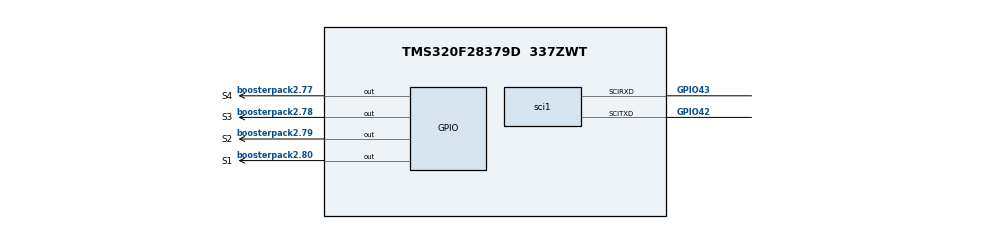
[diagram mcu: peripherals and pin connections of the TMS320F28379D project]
/**
 * These arguments were used when this file was generated. They will be automatically applied on subsequent loads
 * via the GUI or CLI. Run CLI with '--help' for additional information on how to override these arguments.
 * @cliArgs --board "/boards/LAUNCHXL_F28379D" --device "F2837xD" --part "F2837xD_337ZWT" --package "F2837xD_337ZWT" --context "CPU1" --product "C2000WARE@26.00.00.00"
 * @v2CliArgs --board "/boards/LAUNCHXL_F28379D" --device "TMS320F28379D" --package "337ZWT" --context "CPU1" --product "C2000WARE@26.00.00.00"
 * @versions {"tool":"1.27.0+4565"}
 */

/**
 * Import the modules used in this configuration.
 */
const cla              = scripting.addModule("/driverlib/cla.js", {}, false);
const cla1             = cla.addInstance();
const cputimer         = scripting.addModule("/driverlib/cputimer.js", {}, false);
const cputimer1        = cputimer.addInstance();
const gpio             = scripting.addModule("/driverlib/gpio.js", {}, false);
const gpio1            = gpio.addInstance();
const gpio2            = gpio.addInstance();
const gpio3            = gpio.addInstance();
const gpio4            = gpio.addInstance();
const inputxbar_input  = scripting.addModule("/driverlib/inputxbar_input.js", {}, false);
const inputxbar_input1 = inputxbar_input.addInstance();
const inputxbar_input2 = inputxbar_input.addInstance();
const inputxbar_input3 = inputxbar_input.addInstance();
const inputxbar_input4 = inputxbar_input.addInstance();
const memcfg           = scripting.addModule("/driverlib/memcfg.js");
const sci              = scripting.addModule("/driverlib/sci.js", {}, false);
const sci1             = sci.addInstance();

/**
 * Write custom configuration values to the imported modules.
 */
cla1.$name             = "myCLA0";
cla1.enable_CLA_TASK_2 = false;
cla1.enable_CLA_TASK_3 = false;
cla1.enable_CLA_TASK_4 = false;
cla1.enable_CLA_TASK_5 = false;
cla1.enable_CLA_TASK_6 = false;
cla1.enable_CLA_TASK_8 = false;
cla1.enable_CLA_TASK_7 = false;
cla1.cpuint_CLA_TASK_2 = false;
cla1.cpuint_CLA_TASK_3 = false;
cla1.cpuint_CLA_TASK_4 = false;
cla1.cpuint_CLA_TASK_5 = false;
cla1.cpuint_CLA_TASK_6 = false;
cla1.cpuint_CLA_TASK_7 = false;
cla1.cpuint_CLA_TASK_8 = false;

cputimer1.$name                    = "myCPUTIMER0";
cputimer1.timerPeriod              = 499;
cputimer1.enableInterrupt          = true;
cputimer1.startTimer               = true;
cputimer1.registerInterrupts       = true;
cputimer1.timerInt.enableInterrupt = true;

gpio1.$name                     = "S1";
gpio1.useInterrupt              = true;
gpio1.gpioPin.$assign           = "boosterpack2.80";
gpio1.xint.intType              = "GPIO_INT_TYPE_BOTH_EDGES";
gpio1.xint.enableInt            = true;
gpio1.xint.registerInterrupts   = true;
gpio1.xint.xInt.enableInterrupt = true;
scripting.suppress("Connected to hardware,@@@.+?@@@ is connected to EPWM4 BP on the LaunchPad F28379D\\. Consider selecting it in \'use hardware\' above\\. @@@.+?@@@", gpio1, "gpioPin");

gpio2.$name                     = "S2";
gpio2.useInterrupt              = true;
gpio2.gpioPin.$assign           = "boosterpack2.79";
gpio2.xint.intType              = "GPIO_INT_TYPE_BOTH_EDGES";
gpio2.xint.enableInt            = true;
gpio2.xint.registerInterrupts   = true;
gpio2.xint.xintNum              = "GPIO_INT_XINT2";
gpio2.xint.xInt.enableInterrupt = true;
scripting.suppress("Connected to hardware,@@@.+?@@@ is connected to EPWM4 BP on the LaunchPad F28379D\\. Consider selecting it in \'use hardware\' above\\. @@@.+?@@@", gpio2, "gpioPin");

gpio3.$name                     = "S3";
gpio3.useInterrupt              = true;
gpio3.gpioPin.$assign           = "boosterpack2.78";
gpio3.xint.intType              = "GPIO_INT_TYPE_BOTH_EDGES";
gpio3.xint.enableInt            = true;
gpio3.xint.registerInterrupts   = true;
gpio3.xint.xintNum              = "GPIO_INT_XINT3";
gpio3.xint.xInt.enableInterrupt = true;
scripting.suppress("Connected to hardware,@@@.+?@@@ is connected to EPWM5 BP on the LaunchPad F28379D\\. Consider selecting it in \'use hardware\' above\\. @@@.+?@@@", gpio3, "gpioPin");

gpio4.$name                     = "S4";
gpio4.useInterrupt              = true;
gpio4.gpioPin.$assign           = "boosterpack2.77";
gpio4.xint.intType              = "GPIO_INT_TYPE_BOTH_EDGES";
gpio4.xint.enableInt            = true;
gpio4.xint.registerInterrupts   = true;
gpio4.xint.xintNum              = "GPIO_INT_XINT4";
gpio4.xint.xInt.enableInterrupt = true;
scripting.suppress("Connected to hardware,@@@.+?@@@ is connected to EPWM5 BP on the LaunchPad F28379D\\. Consider selecting it in \'use hardware\' above\\. @@@.+?@@@", gpio4, "gpioPin");

inputxbar_input1.$name         = "myINPUTXBARINPUT0";
gpio1.xint.inputxbar           = inputxbar_input1;
inputxbar_input1.inputxbarGpio = "GPIO6";

inputxbar_input2.$name         = "myINPUTXBARINPUT1";
gpio2.xint.inputxbar           = inputxbar_input2;
inputxbar_input2.inputxbarGpio = "GPIO7";

inputxbar_input3.$name         = "myINPUTXBARINPUT2";
gpio3.xint.inputxbar           = inputxbar_input3;
inputxbar_input3.inputxbarGpio = "GPIO8";

inputxbar_input4.$name         = "myINPUTXBARINPUT3";
gpio4.xint.inputxbar           = inputxbar_input4;
inputxbar_input4.inputxbarGpio = "GPIO9";

memcfg.config_MEMCFG_SECT_LS1 = "CLA_data";
memcfg.config_MEMCFG_SECT_LS4 = "CLA_prog";
memcfg.config_MEMCFG_SECT_LS5 = "CLA_prog";

sci1.$name                      = "SCI0";
sci1.selectRegisteredInterrupts = ["registerRxInt"];
sci1.enabledFIFOInterrupts      = ["SCI_INT_RXFF"];
sci1.rxFifo                     = "SCI_FIFO_RX4";
sci1.sci.scirxdPin.$assign      = "GPIO43";
sci1.sci.scitxdPin.$assign      = "GPIO42";
sci1.rxQual.$name               = "myGPIOQUAL0";
sci1.txQual.$name               = "myGPIOQUAL1";
sci1.sciRXInt.enableInterrupt   = true;

/**
 * Pinmux solution for unlocked pins/peripherals. This ensures that minor changes to the automatic solver in a future
 * version of the tool will not impact the pinmux you originally saw.  These lines can be completely deleted in order to
 * re-solve from scratch.
 */
sci1.sci.$suggestSolution = "SCIA";
